VERSION ""

NS_ :

BS_:

BU_:

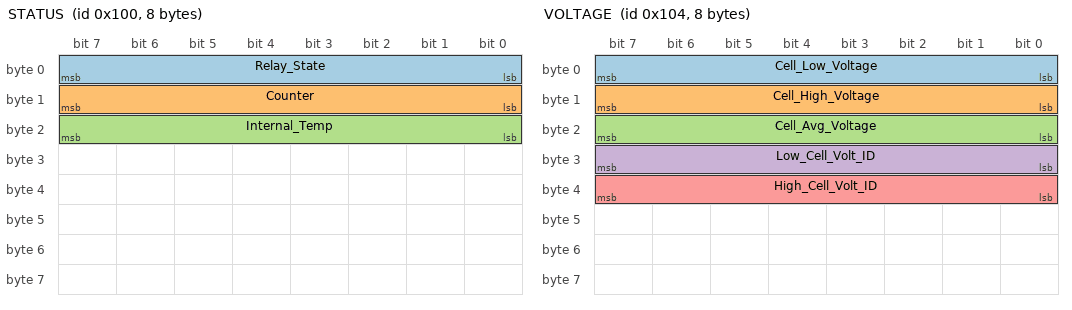
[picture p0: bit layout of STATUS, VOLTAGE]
BO_ 256 STATUS: 8 Vector__XXX
 SG_ Relay_State : 0|8@1+ (1,0) [0|0] "" Vector__XXX
 SG_ Counter : 8|8@1+ (1,0) [0|0] "" Vector__XXX
 SG_ Internal_Temp : 16|8@1+ (1,0) [0|0] "°C" Vector__XXX

BO_ 260 VOLTAGE: 8 Vector__XXX
 SG_ Cell_Low_Voltage : 0|8@1+ (1,0) [0|0] "V" Vector__XXX
 SG_ Cell_High_Voltage : 8|8@1+ (1,0) [0|0] "V" Vector__XXX
 SG_ Cell_Avg_Voltage : 16|8@1+ (1,0) [0|0] "V" Vector__XXX
 SG_ Low_Cell_Volt_ID : 24|8@1+ (1,0) [0|0] "" Vector__XXX
 SG_ High_Cell_Volt_ID : 32|8@1+ (1,0) [0|0] "" Vector__XXX

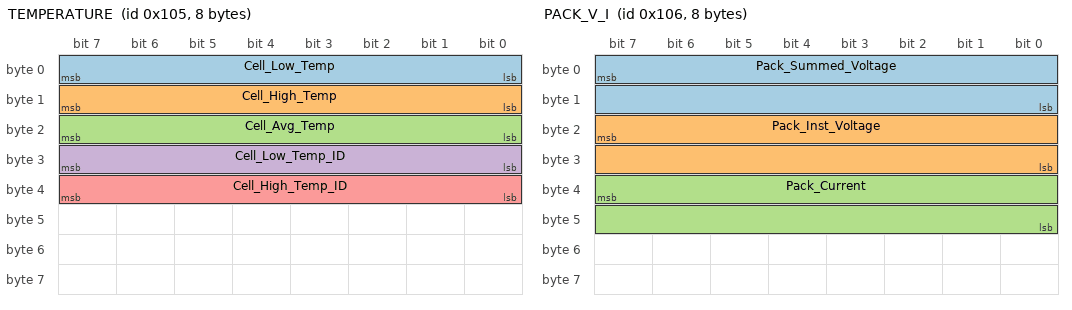
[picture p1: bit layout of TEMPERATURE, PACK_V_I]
BO_ 261 TEMPERATURE: 8 Vector__XXX
 SG_ Cell_Low_Temp : 0|8@1+ (1,0) [0|0] "" Vector__XXX
 SG_ Cell_High_Temp : 8|8@1+ (1,0) [0|0] "" Vector__XXX
 SG_ Cell_Avg_Temp : 16|8@1+ (1,0) [0|0] "" Vector__XXX
 SG_ Cell_Low_Temp_ID : 24|8@1+ (1,0) [0|0] "" Vector__XXX
 SG_ Cell_High_Temp_ID : 32|8@1+ (1,0) [0|0] "" Vector__XXX

BO_ 262 PACK_V_I: 8 Vector__XXX
 SG_ Pack_Summed_Voltage : 7|16@0+ (0.1,0) [0|0] "" Vector__XXX
 SG_ Pack_Inst_Voltage : 23|16@0+ (0.1,0) [0|0] "" Vector__XXX
 SG_ Pack_Current : 39|16@0+ (0.1,0) [0|0] "" Vector__XXX

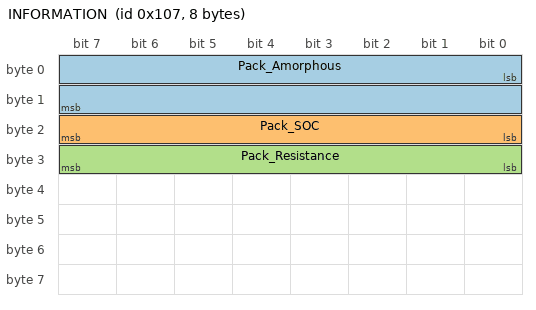
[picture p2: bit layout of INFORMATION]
BO_ 263 INFORMATION: 8 Vector__XXX
 SG_ Pack_Amorphous : 0|16@1+ (1,0) [0|0] "" Vector__XXX
 SG_ Pack_SOC : 16|8@1+ (1,0) [0|0] "" Vector__XXX
 SG_ Pack_Resistance : 24|8@1+ (1,0) [0|0] "" Vector__XXX
